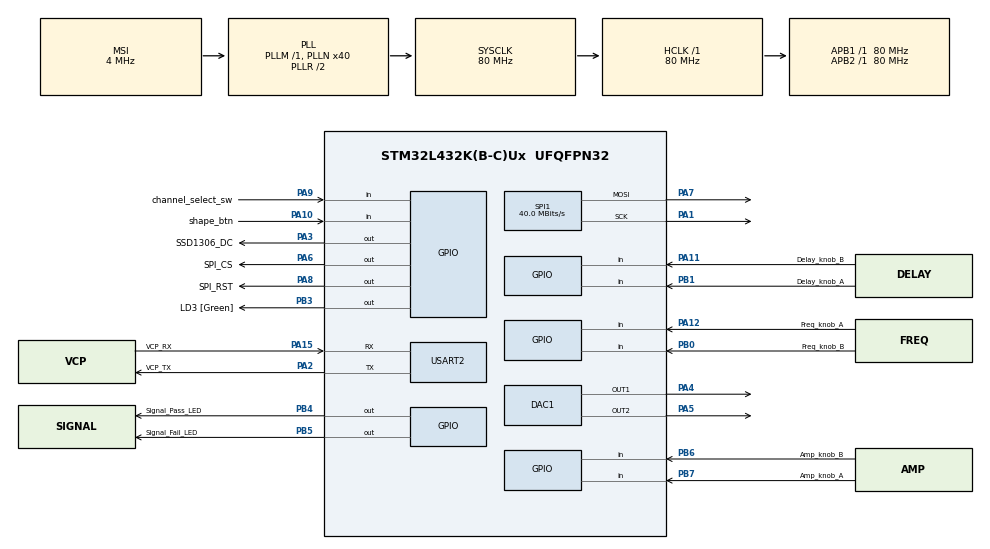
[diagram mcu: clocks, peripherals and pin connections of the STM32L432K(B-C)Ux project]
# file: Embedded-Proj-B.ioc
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DAC1.DAC_Channel-DAC_OUT2_ExtAndInt=DAC_CHANNEL_2
DAC1.DAC_SampleAndHold-DAC_OUT1_ExtAndInt=DAC_SAMPLEANDHOLD_DISABLE
DAC1.DAC_SampleAndHold-DAC_OUT2_ExtAndInt=DAC_SAMPLEANDHOLD_DISABLE
DAC1.DAC_Trigger-DAC_OUT1_ExtAndInt=DAC_TRIGGER_T2_TRGO
DAC1.DAC_Trigger-DAC_OUT2_ExtAndInt=DAC_TRIGGER_T6_TRGO
Dma.DAC_CH1.0.Direction=DMA_MEMORY_TO_PERIPH
Dma.DAC_CH1.0.Instance=DMA1_Channel3
Dma.DAC_CH1.0.MemDataAlignment=DMA_MDATAALIGN_WORD
Dma.DAC_CH1.0.MemInc=DMA_MINC_ENABLE
Dma.DAC_CH1.0.Mode=DMA_CIRCULAR
Dma.DAC_CH1.0.PeriphDataAlignment=DMA_PDATAALIGN_WORD
Dma.DAC_CH1.0.PeriphInc=DMA_PINC_DISABLE
Dma.DAC_CH1.0.Priority=DMA_PRIORITY_HIGH
Dma.DAC_CH2.1.Direction=DMA_MEMORY_TO_PERIPH
Dma.DAC_CH2.1.Instance=DMA1_Channel4
Dma.DAC_CH2.1.MemDataAlignment=DMA_MDATAALIGN_WORD
Dma.DAC_CH2.1.MemInc=DMA_MINC_ENABLE
Dma.DAC_CH2.1.Mode=DMA_CIRCULAR
Dma.DAC_CH2.1.PeriphDataAlignment=DMA_PDATAALIGN_WORD
Dma.DAC_CH2.1.PeriphInc=DMA_PINC_DISABLE
Dma.DAC_CH2.1.Priority=DMA_PRIORITY_HIGH
Dma.Request0=DAC_CH1
Dma.Request1=DAC_CH2
Mcu.Family=STM32L4
Mcu.Name=STM32L432K(B-C)Ux
Mcu.Package=UFQFPN32
NVIC.DMA1_Channel3_IRQn=true\:0\:0\:false\:false\:true\:false\:true\:true
NVIC.DMA1_Channel4_IRQn=true\:0\:0\:false\:false\:true\:false\:true\:true
NVIC.PriorityGroup=NVIC_PRIORITYGROUP_4
NVIC.TIM2_IRQn=true\:0\:0\:false\:false\:true\:true\:true\:true
NVIC.TIM6_DAC_IRQn=true\:0\:0\:false\:false\:true\:true\:true\:true
NVIC.TIM7_IRQn=true\:0\:0\:false\:false\:true\:true\:true\:true
PA0.GPIO_Label=MCO [High speed clock in]
PA0.Mode=HSE-External-Clock-Source-for-LittleOrca
PA0.Signal=RCC_CK_IN
PA1.Mode=TX_Only_Simplex_Unidirect_Master
PA1.Signal=SPI1_SCK
PA10.GPIO_Label=shape_btn
PA10.GPIO_PuPd=GPIO_PULLUP
PA10.Signal=GPIO_Input
PA11.GPIO_Label=Delay_knob_B
PA11.GPIO_PuPd=GPIO_PULLUP
PA11.Signal=GPIO_Input
PA12.GPIO_Label=Freq_knob_A
PA12.GPIO_PuPd=GPIO_PULLUP
PA12.Signal=GPIO_Input
PA13\ (JTMS-SWDIO).GPIO_Label=SWDIO
PA13\ (JTMS-SWDIO).Mode=Serial_Wire
PA13\ (JTMS-SWDIO).Signal=SYS_JTMS-SWDIO
PA14\ (JTCK-SWCLK).GPIO_Label=SWCLK
PA14\ (JTCK-SWCLK).Mode=Serial_Wire
PA14\ (JTCK-SWCLK).Signal=SYS_JTCK-SWCLK
PA15\ (JTDI).GPIO_Label=VCP_RX
PA15\ (JTDI).Mode=Asynchronous
PA15\ (JTDI).Signal=USART2_RX
PA2.GPIO_Label=VCP_TX
PA2.Mode=Asynchronous
PA2.Signal=USART2_TX
PA3.GPIO_Label=SSD1306_DC
PA3.Signal=GPIO_Output
PA4.Signal=COMP_DAC11_group
PA5.Signal=COMP_DAC12_group
PA6.GPIO_Label=SPI_CS
PA6.Signal=GPIO_Output
PA7.Mode=TX_Only_Simplex_Unidirect_Master
PA7.Signal=SPI1_MOSI
PA8.GPIO_Label=SPI_RST
PA8.Signal=GPIO_Output
PA9.GPIO_Label=channel_select_sw
PA9.GPIO_PuPd=GPIO_PULLUP
PA9.Signal=GPIO_Input
PB0.GPIO_Label=Freq_knob_B
PB0.GPIO_PuPd=GPIO_PULLUP
PB0.Signal=GPIO_Input
PB1.GPIO_Label=Delay_knob_A
PB1.GPIO_PuPd=GPIO_PULLUP
PB1.Signal=GPIO_Input
PB3\ (JTDO-TRACESWO).GPIO_Label=LD3 [Green]
PB3\ (JTDO-TRACESWO).Signal=GPIO_Output
PB4\ (NJTRST).GPIO_Label=Signal_Pass_LED
PB4\ (NJTRST).Signal=GPIO_Output
PB5.GPIO_Label=Signal_Fail_LED
PB5.Signal=GPIO_Output
PB6.GPIO_Label=Amp_knob_B
PB6.GPIO_PuPd=GPIO_PULLUP
PB6.Signal=GPIO_Input
PB7.GPIO_Label=Amp_knob_A
PB7.GPIO_PuPd=GPIO_PULLUP
PB7.Signal=GPIO_Input
PC14-OSC32_IN\ (PC14).Mode=LSE-External-Oscillator
PC14-OSC32_IN\ (PC14).Signal=RCC_OSC32_IN
PC15-OSC32_OUT\ (PC15).Mode=LSE-External-Oscillator
PC15-OSC32_OUT\ (PC15).Signal=RCC_OSC32_OUT
ProjectManager.HeapSize=0x200
ProjectManager.StackSize=0x400
ProjectManager.TargetToolchain=STM32CubeIDE
RCC.AHBFreq_Value=80000000
RCC.APB1Freq_Value=80000000
RCC.APB1TimFreq_Value=80000000
RCC.APB2Freq_Value=80000000
RCC.APB2TimFreq_Value=80000000
RCC.CortexFreq_Value=80000000
RCC.HCLKFreq_Value=80000000
RCC.HSE_VALUE=8000000
RCC.HSI16_VALUE=16000000
RCC.HSI48_VALUE=48000000
RCC.HSI_VALUE=16000000
RCC.MSI_VALUE=4000000
RCC.PLLMUL=RCC_PLLMUL_4
RCC.PLLN=40
RCC.SYSCLKFreq_VALUE=80000000
RCC.SYSCLKSource=RCC_SYSCLKSOURCE_PLLCLK
RCC.VCOOutputFreq_Value=160000000
SH.COMP_DAC11_group.0=DAC1_OUT1,DAC_OUT1_ExtAndInt
SH.COMP_DAC12_group.0=DAC1_OUT2,DAC_OUT2_ExtAndInt
SPI1.BaudRatePrescaler=SPI_BAUDRATEPRESCALER_2
SPI1.CalculateBaudRate=40.0 MBits/s
SPI1.DataSize=SPI_DATASIZE_8BIT
SPI1.Direction=SPI_DIRECTION_2LINES
SPI1.Mode=SPI_MODE_MASTER
SPI1.VirtualType=VM_MASTER
TIM2.AutoReloadPreload=TIM_AUTORELOAD_PRELOAD_DISABLE
TIM2.Period=2731
TIM2.Prescaler=4
TIM2.TIM_MasterOutputTrigger=TIM_TRGO_UPDATE
TIM6.Period=2731
TIM6.Prescaler=4
TIM6.TIM_MasterOutputTrigger=TIM_TRGO_UPDATE
TIM7.Period=9999
TIM7.Prescaler=15
USART2.VirtualMode-Asynchronous=VM_ASYNC
VP_TIM2_VS_ClockSourceINT.Mode=Internal
VP_TIM6_VS_ClockSourceINT.Mode=Enable_Timer
VP_TIM7_VS_ClockSourceINT.Mode=Enable_Timer
board=NUCLEO-L432KC

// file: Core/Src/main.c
/* USER CODE BEGIN Header */
/**
  ******************************************************************************
  * @file           : main.c
  * @brief          : Main program body
  ******************************************************************************
  * @attention
  *
  * Copyright (c) 2024 STMicroelectronics.
  * All rights reserved.
  *
  * This software is licensed under terms that can be found in the LICENSE file
  * in the root directory of this software component.
  * If no LICENSE file comes with this software, it is provided AS-IS.
  *
  ******************************************************************************
  */
/* USER CODE END Header */
#include "main.h"

/* USER CODE BEGIN PTD */
void cpp_main(void);
/* USER CODE END PTD */

DAC_HandleTypeDef hdac1;
DMA_HandleTypeDef hdma_dac_ch1;
DMA_HandleTypeDef hdma_dac_ch2;

SPI_HandleTypeDef hspi1;

TIM_HandleTypeDef htim2;
TIM_HandleTypeDef htim6;
TIM_HandleTypeDef htim7;

UART_HandleTypeDef huart2;

void SystemClock_Config(void);
static void MX_GPIO_Init(void);
static void MX_DMA_Init(void);
static void MX_USART2_UART_Init(void);
static void MX_DAC1_Init(void);
static void MX_TIM2_Init(void);
static void MX_TIM6_Init(void);
static void MX_SPI1_Init(void);
static void MX_TIM7_Init(void);
/* USER CODE BEGIN PFP */

//
static void MX_TIM7_Init(void);
/* USER CODE BEGIN PFP */
void myTIM7_IRQHandler();
/* USER CODE END PFP */

int main(void)
{

  /* MCU Configuration--------------------------------------------------------*/

  /* Reset of all peripherals, Initializes the Flash interface and the Systick. */
  HAL_Init();

  /* Configure the system clock */
  SystemClock_Config();

  /* Initialize all configured peripherals */
  MX_GPIO_Init();
  MX_DMA_Init();
  MX_USART2_UART_Init();
  MX_DAC1_Init();
  MX_TIM2_Init();
  MX_TIM6_Init();
  MX_SPI1_Init();
  MX_TIM7_Init();
  /* USER CODE BEGIN 2 */
  HAL_TIM_Base_Start_IT(&htim7);
  /* USER CODE END 2 */

  /* Infinite loop */
  /* USER CODE BEGIN WHILE */
  cpp_main();
  while (1)
  {
    /* USER CODE END WHILE */

  }
}

void SystemClock_Config(void)
{
  RCC_OscInitTypeDef RCC_OscInitStruct = {0};
  RCC_ClkInitTypeDef RCC_ClkInitStruct = {0};

  /** Configure the main internal regulator output voltage
  */
  if (HAL_PWREx_ControlVoltageScaling(PWR_REGULATOR_VOLTAGE_SCALE1) != HAL_OK)
  {
    Error_Handler();
  }

  /** Configure LSE Drive Capability
  */
  HAL_PWR_EnableBkUpAccess();
  __HAL_RCC_LSEDRIVE_CONFIG(RCC_LSEDRIVE_LOW);

  /** Initializes the RCC Oscillators according to the specified parameters
  * in the RCC_OscInitTypeDef structure.
  */
  RCC_OscInitStruct.OscillatorType = RCC_OSCILLATORTYPE_LSE|RCC_OSCILLATORTYPE_MSI;
  RCC_OscInitStruct.LSEState = RCC_LSE_ON;
  RCC_OscInitStruct.MSIState = RCC_MSI_ON;
  RCC_OscInitStruct.MSICalibrationValue = 0;
  RCC_OscInitStruct.MSIClockRange = RCC_MSIRANGE_6;
  RCC_OscInitStruct.PLL.PLLState = RCC_PLL_ON;
  RCC_OscInitStruct.PLL.PLLSource = RCC_PLLSOURCE_MSI;
  RCC_OscInitStruct.PLL.PLLM = 1;
  RCC_OscInitStruct.PLL.PLLN = 40;
  RCC_OscInitStruct.PLL.PLLP = RCC_PLLP_DIV7;
  RCC_OscInitStruct.PLL.PLLQ = RCC_PLLQ_DIV2;
  RCC_OscInitStruct.PLL.PLLR = RCC_PLLR_DIV2;
  if (HAL_RCC_OscConfig(&RCC_OscInitStruct) != HAL_OK)
  {
    Error_Handler();
  }

  /** Initializes the CPU, AHB and APB buses clocks
  */
  RCC_ClkInitStruct.ClockType = RCC_CLOCKTYPE_HCLK|RCC_CLOCKTYPE_SYSCLK
                              |RCC_CLOCKTYPE_PCLK1|RCC_CLOCKTYPE_PCLK2;
  RCC_ClkInitStruct.SYSCLKSource = RCC_SYSCLKSOURCE_PLLCLK;
  RCC_ClkInitStruct.AHBCLKDivider = RCC_SYSCLK_DIV1;
  RCC_ClkInitStruct.APB1CLKDivider = RCC_HCLK_DIV1;
  RCC_ClkInitStruct.APB2CLKDivider = RCC_HCLK_DIV1;

  if (HAL_RCC_ClockConfig(&RCC_ClkInitStruct, FLASH_LATENCY_4) != HAL_OK)
  {
    Error_Handler();
  }

  /** Enable MSI Auto calibration
  */
  HAL_RCCEx_EnableMSIPLLMode();
}

static void MX_DAC1_Init(void)
{

  DAC_ChannelConfTypeDef sConfig = {0};

  /** DAC Initialization
  */
  hdac1.Instance = DAC1;
  if (HAL_DAC_Init(&hdac1) != HAL_OK)
  {
    Error_Handler();
  }

  /** DAC channel OUT1 config
  */
  sConfig.DAC_SampleAndHold = DAC_SAMPLEANDHOLD_DISABLE;
  sConfig.DAC_Trigger = DAC_TRIGGER_T2_TRGO;
  sConfig.DAC_OutputBuffer = DAC_OUTPUTBUFFER_ENABLE;
  sConfig.DAC_ConnectOnChipPeripheral = DAC_CHIPCONNECT_ENABLE;
  sConfig.DAC_UserTrimming = DAC_TRIMMING_FACTORY;
  if (HAL_DAC_ConfigChannel(&hdac1, &sConfig, DAC_CHANNEL_1) != HAL_OK)
  {
    Error_Handler();
  }

  /** DAC channel OUT2 config
  */
  sConfig.DAC_Trigger = DAC_TRIGGER_T6_TRGO;
  if (HAL_DAC_ConfigChannel(&hdac1, &sConfig, DAC_CHANNEL_2) != HAL_OK)
  {
    Error_Handler();
  }

}

static void MX_SPI1_Init(void)
{

  /* SPI1 parameter configuration*/
  hspi1.Instance = SPI1;
  hspi1.Init.Mode = SPI_MODE_MASTER;
  hspi1.Init.Direction = SPI_DIRECTION_2LINES;
  hspi1.Init.DataSize = SPI_DATASIZE_8BIT;
  hspi1.Init.CLKPolarity = SPI_POLARITY_LOW;
  hspi1.Init.CLKPhase = SPI_PHASE_1EDGE;
  hspi1.Init.NSS = SPI_NSS_SOFT;
  hspi1.Init.BaudRatePrescaler = SPI_BAUDRATEPRESCALER_2;
  hspi1.Init.FirstBit = SPI_FIRSTBIT_MSB;
  hspi1.Init.TIMode = SPI_TIMODE_DISABLE;
  hspi1.Init.CRCCalculation = SPI_CRCCALCULATION_DISABLE;
  hspi1.Init.CRCPolynomial = 7;
  hspi1.Init.CRCLength = SPI_CRC_LENGTH_DATASIZE;
  hspi1.Init.NSSPMode = SPI_NSS_PULSE_ENABLE;
  if (HAL_SPI_Init(&hspi1) != HAL_OK)
  {
    Error_Handler();
  }

}

static void MX_TIM2_Init(void)
{

  TIM_ClockConfigTypeDef sClockSourceConfig = {0};
  TIM_MasterConfigTypeDef sMasterConfig = {0};

  htim2.Instance = TIM2;
  htim2.Init.Prescaler = 4;
  htim2.Init.CounterMode = TIM_COUNTERMODE_UP;
  htim2.Init.Period = 2731;
  htim2.Init.ClockDivision = TIM_CLOCKDIVISION_DIV1;
  htim2.Init.AutoReloadPreload = TIM_AUTORELOAD_PRELOAD_DISABLE;
  if (HAL_TIM_Base_Init(&htim2) != HAL_OK)
  {
    Error_Handler();
  }
  sClockSourceConfig.ClockSource = TIM_CLOCKSOURCE_INTERNAL;
  if (HAL_TIM_ConfigClockSource(&htim2, &sClockSourceConfig) != HAL_OK)
  {
    Error_Handler();
  }
  sMasterConfig.MasterOutputTrigger = TIM_TRGO_UPDATE;
  sMasterConfig.MasterSlaveMode = TIM_MASTERSLAVEMODE_DISABLE;
  if (HAL_TIMEx_MasterConfigSynchronization(&htim2, &sMasterConfig) != HAL_OK)
  {
    Error_Handler();
  }

}

static void MX_TIM6_Init(void)
{

  TIM_MasterConfigTypeDef sMasterConfig = {0};

  htim6.Instance = TIM6;
  htim6.Init.Prescaler = 4;
  htim6.Init.CounterMode = TIM_COUNTERMODE_UP;
  htim6.Init.Period = 2731;
  htim6.Init.AutoReloadPreload = TIM_AUTORELOAD_PRELOAD_DISABLE;
  if (HAL_TIM_Base_Init(&htim6) != HAL_OK)
  {
    Error_Handler();
  }
  sMasterConfig.MasterOutputTrigger = TIM_TRGO_UPDATE;
  sMasterConfig.MasterSlaveMode = TIM_MASTERSLAVEMODE_DISABLE;
  if (HAL_TIMEx_MasterConfigSynchronization(&htim6, &sMasterConfig) != HAL_OK)
  {
    Error_Handler();
  }

}

static void MX_TIM7_Init(void)
{

  TIM_MasterConfigTypeDef sMasterConfig = {0};

  htim7.Instance = TIM7;
  htim7.Init.Prescaler = 15;
  htim7.Init.CounterMode = TIM_COUNTERMODE_UP;
  htim7.Init.Period = 9999;
  htim7.Init.AutoReloadPreload = TIM_AUTORELOAD_PRELOAD_DISABLE;
  if (HAL_TIM_Base_Init(&htim7) != HAL_OK)
  {
    Error_Handler();
  }
  sMasterConfig.MasterOutputTrigger = TIM_TRGO_RESET;
  sMasterConfig.MasterSlaveMode = TIM_MASTERSLAVEMODE_DISABLE;
  if (HAL_TIMEx_MasterConfigSynchronization(&htim7, &sMasterConfig) != HAL_OK)
  {
    Error_Handler();
  }

}

static void MX_USART2_UART_Init(void)
{

  huart2.Instance = USART2;
  huart2.Init.BaudRate = 115200;
  huart2.Init.WordLength = UART_WORDLENGTH_8B;
  huart2.Init.StopBits = UART_STOPBITS_1;
  huart2.Init.Parity = UART_PARITY_NONE;
  huart2.Init.Mode = UART_MODE_TX_RX;
  huart2.Init.HwFlowCtl = UART_HWCONTROL_NONE;
  huart2.Init.OverSampling = UART_OVERSAMPLING_16;
  huart2.Init.OneBitSampling = UART_ONE_BIT_SAMPLE_DISABLE;
  huart2.AdvancedInit.AdvFeatureInit = UART_ADVFEATURE_NO_INIT;
  if (HAL_UART_Init(&huart2) != HAL_OK)
  {
    Error_Handler();
  }

}

static void MX_DMA_Init(void)
{

  /* DMA controller clock enable */
  __HAL_RCC_DMA1_CLK_ENABLE();

  /* DMA interrupt init */
  /* DMA1_Channel3_IRQn interrupt configuration */
  HAL_NVIC_SetPriority(DMA1_Channel3_IRQn, 0, 0);
  HAL_NVIC_EnableIRQ(DMA1_Channel3_IRQn);
  /* DMA1_Channel4_IRQn interrupt configuration */
  HAL_NVIC_SetPriority(DMA1_Channel4_IRQn, 0, 0);
  HAL_NVIC_EnableIRQ(DMA1_Channel4_IRQn);

}

static void MX_GPIO_Init(void)
{
  LL_GPIO_InitTypeDef GPIO_InitStruct = {0};

  /* GPIO Ports Clock Enable */
  LL_AHB2_GRP1_EnableClock(LL_AHB2_GRP1_PERIPH_GPIOC);
  LL_AHB2_GRP1_EnableClock(LL_AHB2_GRP1_PERIPH_GPIOA);
  LL_AHB2_GRP1_EnableClock(LL_AHB2_GRP1_PERIPH_GPIOB);

  /**/
  LL_GPIO_ResetOutputPin(GPIOA, SSD1306_DC_Pin|SPI_CS_Pin|SPI_RST_Pin);

  /**/
  LL_GPIO_ResetOutputPin(GPIOB, LD3_Pin|Signal_Pass_LED_Pin|Signal_Fail_LED_Pin);

  /**/
  GPIO_InitStruct.Pin = SSD1306_DC_Pin|SPI_CS_Pin|SPI_RST_Pin;
  GPIO_InitStruct.Mode = LL_GPIO_MODE_OUTPUT;
  GPIO_InitStruct.Speed = LL_GPIO_SPEED_FREQ_LOW;
  GPIO_InitStruct.OutputType = LL_GPIO_OUTPUT_PUSHPULL;
  GPIO_InitStruct.Pull = LL_GPIO_PULL_NO;
  LL_GPIO_Init(GPIOA, &GPIO_InitStruct);

  /**/
  GPIO_InitStruct.Pin = Freq_knob_B_Pin|Delay_knob_A_Pin|Amp_knob_B_Pin|Amp_knob_A_Pin;
  GPIO_InitStruct.Mode = LL_GPIO_MODE_INPUT;
  GPIO_InitStruct.Pull = LL_GPIO_PULL_UP;
  LL_GPIO_Init(GPIOB, &GPIO_InitStruct);

  /**/
  GPIO_InitStruct.Pin = channel_select_sw_Pin|shape_btn_Pin|Delay_knob_B_Pin|Freq_knob_A_Pin;
  GPIO_InitStruct.Mode = LL_GPIO_MODE_INPUT;
  GPIO_InitStruct.Pull = LL_GPIO_PULL_UP;
  LL_GPIO_Init(GPIOA, &GPIO_InitStruct);

  /**/
  GPIO_InitStruct.Pin = LD3_Pin|Signal_Pass_LED_Pin|Signal_Fail_LED_Pin;
  GPIO_InitStruct.Mode = LL_GPIO_MODE_OUTPUT;
  GPIO_InitStruct.Speed = LL_GPIO_SPEED_FREQ_LOW;
  GPIO_InitStruct.OutputType = LL_GPIO_OUTPUT_PUSHPULL;
  GPIO_InitStruct.Pull = LL_GPIO_PULL_NO;
  LL_GPIO_Init(GPIOB, &GPIO_InitStruct);

}

void Error_Handler(void)
{
  __disable_irq();
  while (1)
  {
  }
}
